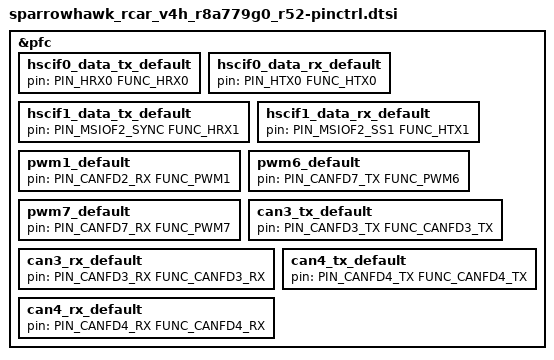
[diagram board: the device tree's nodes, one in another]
/*
 * Copyright (c) 2025 Renesas Electronics Corporation
 *
 * SPDX-License-Identifier: Apache-2.0
 */

#include <dt-bindings/pinctrl/renesas/pinctrl-r8a779g0.h>

&pfc {
	hscif0_data_tx_default: hscif0_data_tx_default {
		pin = <PIN_HRX0 FUNC_HRX0>;
	};

	hscif0_data_rx_default: hscif0_data_rx_default {
		pin = <PIN_HTX0 FUNC_HTX0>;
	};

	hscif1_data_tx_default: hscif1_data_tx_default {
		pin = <PIN_MSIOF2_SYNC FUNC_HRX1>;
	};

	hscif1_data_rx_default: hscif1_data_rx_default {
		pin = <PIN_MSIOF2_SS1 FUNC_HTX1>;
	};

	pwm1_default: pwm1_default {
		pin = <PIN_CANFD2_RX FUNC_PWM1>;
	};

	pwm6_default: pwm6_default {
		pin = <PIN_CANFD7_TX FUNC_PWM6>;
	};

	pwm7_default: pwm7_default {
		pin = <PIN_CANFD7_RX FUNC_PWM7>;
	};

	can3_tx_default: can3_tx_default {
		pin = <PIN_CANFD3_TX FUNC_CANFD3_TX>;
	};

	can3_rx_default: can3_rx_default {
		pin = <PIN_CANFD3_RX FUNC_CANFD3_RX>;
	};

	can4_tx_default: can4_tx_default {
		pin = <PIN_CANFD4_TX FUNC_CANFD4_TX>;
	};

	can4_rx_default: can4_rx_default {
		pin = <PIN_CANFD4_RX FUNC_CANFD4_RX>;
	};
};
